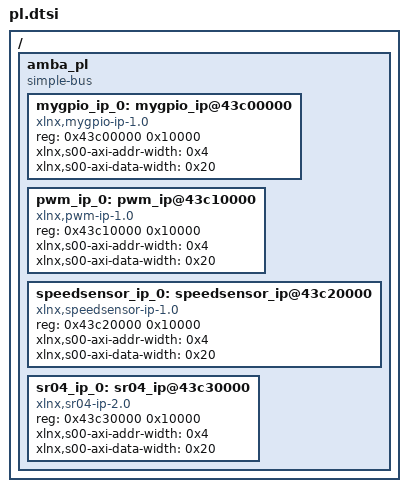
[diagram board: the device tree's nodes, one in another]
/*
 * CAUTION: This file is automatically generated by Xilinx.
 * Version:  
 * Today is: Tue Apr 04 20:59:45 2017
*/


/ {
	amba_pl: amba_pl {
		#address-cells = <1>;
		#size-cells = <1>;
		compatible = "simple-bus";
		ranges ;
		mygpio_ip_0: mygpio_ip@43c00000 {
			compatible = "xlnx,mygpio-ip-1.0";
			reg = <0x43c00000 0x10000>;
			xlnx,s00-axi-addr-width = <0x4>;
			xlnx,s00-axi-data-width = <0x20>;
		};
		pwm_ip_0: pwm_ip@43c10000 {
			compatible = "xlnx,pwm-ip-1.0";
			reg = <0x43c10000 0x10000>;
			xlnx,s00-axi-addr-width = <0x4>;
			xlnx,s00-axi-data-width = <0x20>;
		};
		speedsensor_ip_0: speedsensor_ip@43c20000 {
			compatible = "xlnx,speedsensor-ip-1.0";
			reg = <0x43c20000 0x10000>;
			xlnx,s00-axi-addr-width = <0x4>;
			xlnx,s00-axi-data-width = <0x20>;
		};
		sr04_ip_0: sr04_ip@43c30000 {
			compatible = "xlnx,sr04-ip-2.0";
			reg = <0x43c30000 0x10000>;
			xlnx,s00-axi-addr-width = <0x4>;
			xlnx,s00-axi-data-width = <0x20>;
		};
	};
};
